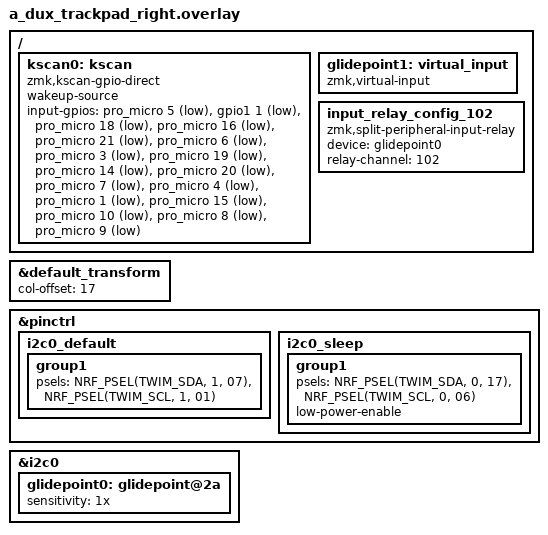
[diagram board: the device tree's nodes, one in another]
/*
 * Copyright (c) 2021 The ZMK Contributors
 *
 * SPDX-License-Identifier: MIT
 */

#include "a_dux_trackpad.dtsi"

&default_transform {
    col-offset = <17>;
};

/{
    kscan0: kscan {
        compatible = "zmk,kscan-gpio-direct";
        wakeup-source;

        input-gpios =
            <&pro_micro  5 (GPIO_ACTIVE_LOW | GPIO_PULL_UP)>,
            <&gpio1 1 (GPIO_ACTIVE_LOW | GPIO_PULL_UP)>,
            // <&pro_micro  0 (GPIO_ACTIVE_LOW | GPIO_PULL_UP)>,
            <&pro_micro 18 (GPIO_ACTIVE_LOW | GPIO_PULL_UP)>,
            <&pro_micro 16 (GPIO_ACTIVE_LOW | GPIO_PULL_UP)>,
            <&pro_micro 21 (GPIO_ACTIVE_LOW | GPIO_PULL_UP)>,
            <&pro_micro  6 (GPIO_ACTIVE_LOW | GPIO_PULL_UP)>,
            <&pro_micro  3 (GPIO_ACTIVE_LOW | GPIO_PULL_UP)>,
            <&pro_micro 19 (GPIO_ACTIVE_LOW | GPIO_PULL_UP)>,
            <&pro_micro 14 (GPIO_ACTIVE_LOW | GPIO_PULL_UP)>,
            <&pro_micro 20 (GPIO_ACTIVE_LOW | GPIO_PULL_UP)>,
            <&pro_micro  7 (GPIO_ACTIVE_LOW | GPIO_PULL_UP)>,
            <&pro_micro  4 (GPIO_ACTIVE_LOW | GPIO_PULL_UP)>,
            <&pro_micro  1 (GPIO_ACTIVE_LOW | GPIO_PULL_UP)>,
            <&pro_micro 15 (GPIO_ACTIVE_LOW | GPIO_PULL_UP)>,
            <&pro_micro 10 (GPIO_ACTIVE_LOW | GPIO_PULL_UP)>,
            <&pro_micro  8 (GPIO_ACTIVE_LOW | GPIO_PULL_UP)>,
            <&pro_micro  9 (GPIO_ACTIVE_LOW | GPIO_PULL_UP)>
        ;
    };
};

&pinctrl {
    
    i2c0_default: i2c0_default {
    group1 {
      psels = <NRF_PSEL(TWIM_SDA, 1, 07)>,
          <NRF_PSEL(TWIM_SCL, 1, 01)>;
    };
    };

    i2c0_sleep: i2c0_sleep {
        group1 {
        psels = <NRF_PSEL(TWIM_SDA, 0, 17)>,
            <NRF_PSEL(TWIM_SCL, 0, 06)>;
        low-power-enable;
        };
    };
};


&i2c0 {
    status = "okay";
    glidepoint0: glidepoint@2a {
        status = "okay";
	
	// trackpad adjust parametres 
	sensitivity = "1x";
	// rotate-90;
        // sleep;
        // no-taps;
	// x-axis-z-min = <5>;
	// y-axis-z-min = <4>;
    };
};

/ {
    /* THIS only makes keymap binding happy, nothing happens on peripheral side */
	glidepoint1: virtual_input {
		compatible = "zmk,virtual-input";
	};

    input_relay_config_102 {
        compatible = "zmk,split-peripheral-input-relay";

        /* peripheral side input device, used to... */
		/*  - be intecepted on peripheral; */
		/*  - and then, be resurrected as `zmk,virtual-device` on central; */
        device = <&glidepoint0>;

        /* channel id, used to be be transfered along with all input events. */
		/* NOTE 1: pick any 8bit integer. (1 - 255) */
		/* NOTE 2: should matching relay-channel on central overlay */
		relay-channel = <102>;
    };
};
